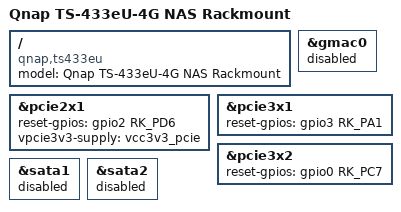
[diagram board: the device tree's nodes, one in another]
// SPDX-License-Identifier: (GPL-2.0-or-later OR MIT)
/*
 * Copyright (c) 2021 Rockchip Electronics Co., Ltd.
 * Copyright (c) 2024 Uwe Kleine-König
 * Copyright (c) 2025 Ahmad Fatoum
 */

#include "rk3568-qnap-ts433.dts"

/ {
	model = "Qnap TS-433eU-4G NAS Rackmount";
	compatible = "qnap,ts433eu", "rockchip,rk3568";
};

/* Built-in MACs not used, 2.5G ports are PCI-connected */
&gmac0 {
	status = "disabled";
};

&pcie2x1 { /* RTL8125 */
	reset-gpios = <&gpio2 RK_PD6 GPIO_ACTIVE_HIGH>;
	vpcie3v3-supply = <&vcc3v3_pcie>;
	status = "okay";
};

&pcie3x1 { /* RTL8125 */
	reset-gpios = <&gpio3 RK_PA1 GPIO_ACTIVE_HIGH>;
};

&pcie3x2 { /* ASM1064 */
	reset-gpios = <&gpio0 RK_PC7 GPIO_ACTIVE_HIGH>;
};

/* Internal SATA controllers not used, ASM1064 used instead */
&sata1 {
	status = "disabled";
};

&sata2 {
	status = "disabled";
};
